VERSION ""

NS_ :

BS_:

BU_: ECU1 ECU2 Gateway

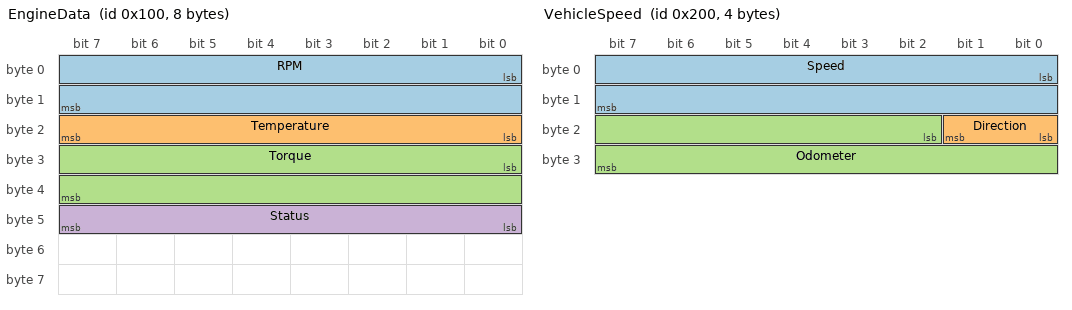
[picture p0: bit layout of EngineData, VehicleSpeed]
BO_ 256 EngineData: 8 ECU1
 SG_ RPM : 0|16@1+ (1,0) [0|8000] "rpm" ECU2
 SG_ Temperature : 16|8@1+ (0.5,-40) [-40|215] "degC" ECU2
 SG_ Torque : 24|16@1+ (0.01,0) [0|655.35] "Nm" ECU2
 SG_ Status : 40|8@1+ (1,0) [0|255] "" ECU2

BO_ 512 VehicleSpeed: 4 ECU2
 SG_ Speed : 0|16@1+ (0.01,0) [0|655.35] "km/h" ECU1
 SG_ Direction : 16|2@1+ (1,0) [0|3] "" ECU1
 SG_ Odometer : 18|14@1+ (0.1,0) [0|1638.3] "km" ECU1

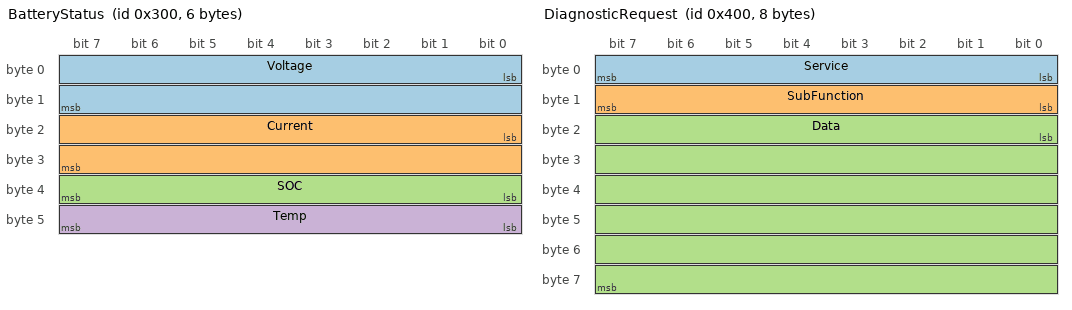
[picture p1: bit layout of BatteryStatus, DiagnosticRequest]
BO_ 768 BatteryStatus: 6 Gateway
 SG_ Voltage : 0|16@1+ (0.001,0) [0|65.535] "V" ECU1
 SG_ Current : 16|16@1+ (0.001,-32.768) [-32.768|32.767] "A" ECU1
 SG_ SOC : 32|8@1+ (0.5,0) [0|100] "%" ECU1
 SG_ Temp : 40|8@1+ (1,-40) [-40|215] "degC" ECU1

BO_ 1024 DiagnosticRequest: 8 ECU1
 SG_ Service : 0|8@1+ (1,0) [0|255] "" Vector__XXX
 SG_ SubFunction : 8|8@1+ (1,0) [0|255] "" Vector__XXX
 SG_ Data : 16|48@1+ (1,0) [0|1.40737e+014] "" Vector__XXX

BO_ 1280 DiagnosticResponse: 8 Gateway
 SG_ Service : 0|8@1+ (1,0) [0|255] "" ECU1
 SG_ Data : 8|56@1+ (1,0) [0|7.20576e+016] "" ECU1

CM_ BU_ ECU1 "Engine Control Unit";
CM_ BU_ ECU2 "Dashboard Control Unit";
CM_ BU_ Gateway "Gateway ECU";
CM_ BO_ 256 "Engine related data";
CM_ SG_ 256 RPM "Engine RPM";
CM_ SG_ 256 Temperature "Engine coolant temperature";
CM_ SG_ 512 Speed "Vehicle speed";

BA_DEF_ BO_ "GenMsgCycleTime" INT 0 65535;
BA_DEF_DEF_ "GenMsgCycleTime" 100;

BA_ "GenMsgCycleTime" BO_ 512 50;
BA_ "GenMsgCycleTime" BO_ 768 1000;

VAL_ 512 Direction 0 "Forward" 1 "Reverse" 2 "Park" 3 "Neutral";
